# RN831X_RN861X_MCU register map
File version: v0.0.1
CPU: RN831X_RN861X_MCU r1p0, little endian, MPU, no FPU
Registers are 32-bit, read-write, reset 0x0 unless marked. A register's access mark holds for its fields unless they carry their own. Offsets are from the block's base; [hi:lo] are bit positions.

## SPI0_CORE0 — SPI0 Module core0
Base 0x20038000
Same registers: SPI1_CORE0 0x2003C000, SPI2_CORE0 0x20040000, SPI3_CORE0 0x20044000, SPI0_CORE1 0xA0038000, SPI1_CORE1 0xA003C000, SPI2_CORE1 0xA0040000, SPI3_CORE1 0xA0044000
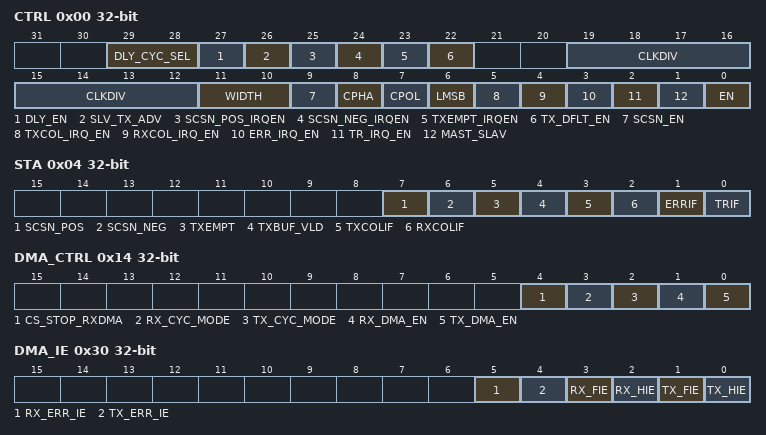
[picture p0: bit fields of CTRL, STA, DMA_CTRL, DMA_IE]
0x00 CTRL — Control Register
  [29:28] DLY_CYC_SEL — Data delay selection (valid only in DMA master mode when delay is enabled).
    0=1CYCLE (Insert 1 SPI_CLK delay per 8-bit data); 1=2CYCLE (Insert 2 SPI_CLK delays per 8-bit data); 2=4CYCLE (Insert 4 SPI_CLK delays per 8-bit data); 3=8CYCLE (Insert 8 SPI_CLK delays per 8-bit data)
  [27] DLY_EN — Delay enable (DMA master mode)
  [26] SLV_TX_ADV — SPI slave high-speed mode enable
  [25] SCSN_POS_IRQEN — SCSN rising edge interrupt enable
  [24] SCSN_NEG_IRQEN — SCSN falling edge interrupt enable
  [23] TXEMPT_IRQEN — TX empty interrupt enable
  [22] TX_DFLT_EN — Behavior when TX buffer is empty
  [19:12] CLKDIV — SCK clock divider factor
  [11:10] WIDTH — Data width selection
    0=8BIT (Data length for SPI transfer: 8 bits); 1=16BIT (Data length for SPI transfer: 16 bits); 2=32BIT (Data length for SPI transfer: 32 bits)
  [9] SCSN_EN — SCSN mode error detection enable (master mode only)
  [8] CPHA — Clock phase selection
  [7] CPOL — Clock polarity
  [6] LMSB — MSB/LSB first selection
  [5] TXCOL_IRQ_EN — TX data conflict interrupt enable
  [4] RXCOL_IRQ_EN — RX data conflict interrupt enable
  [3] ERR_IRQ_EN — SCSN Mode Error Interrupt Enable
  [2] TR_IRQ_EN — Data Transfer Interrupt Enable
  [1] MAST_SLAV — Master/Slave Mode Selection
  [0] EN — SPI Interface Enable
0x04 STA access per field — Status Register
  [7] SCSN_POS rw write-1-clears — Slave mode: CSN rising event flag
  [6] SCSN_NEG rw write-1-clears — Slave mode: CSN falling event flag
  [5] TXEMPT rw write-1-clears — TX empty conflict flag
  [4] TXBUF_VLD ro — TX buffer valid flag
  [3] TXCOLIF rw write-1-clears — TX conflict flag
  [2] RXCOLIF rw write-1-clears — RX overflow flag
  [1] ERRIF rw write-1-clears — SCSN mode error flag
  [0] TRIF rw write-1-clears — Transfer complete flag
0x08 TXDATA access not given — Transmit Data Register
  [31:0] TXDATA — Transmit Data Register. Write valid when enabled.
0x0C RXDATA access not given — Receive Data Register
0x10 TXDFLT access not given — Default Transmit Data Register
0x14 DMA_CTRL — DMA Control Register
  [4] CS_STOP_RXDMA — Disable RX_DMA_EN upon detection of SCSN high level
  [3] RX_CYC_MODE — Receive Cycle Mode Enable
  [2] TX_CYC_MODE — Transmit Cycle Mode Enable
  [1] RX_DMA_EN — Receive DMA Enable
  [0] TX_DMA_EN — Transmit DMA Enable
0x18 DMA_TBADR access not given — DMA Transmit Base Address Register
  [17:0] DMA_TBADR — DMA Transmit Start Address (Byte address).
0x1C DMA_RBADR access not given — DMA Receive Base Address Register
  [17:0] DMA_RBADR — DMA Receive Base Address (Byte address).
0x20 DMA_TLEN access not given — DMA Transmit Length Register
  [17:0] DMA_TLEN — DMA Transmit Length (in Bytes).
0x24 DMA_RLEN access not given — DMA Receive Length Register
  [17:0] DMA_RLEN — DMA Receive Length (in Bytes).
0x28 DMA_TADR ro — Current DMA Transmit Address Register
  [17:0] DMA_TADR — Current DMA Transmit Address (Byte address).
0x2C DMA_RADR ro — Current DMA Receive Address Register
  [17:0] DMA_RADR — Current DMA Receive Address (Byte address).
0x30 DMA_IE — DMA Interrupt Enable Register
  [5] RX_ERR_IE — Receive Data Overwrite Interrupt Enable
  [4] TX_ERR_IE — Transmit Data Error Interrupt Enable
  [3] RX_FIE — DMA Receive Full (Complete) Interrupt Enable
  [2] RX_HIE — DMA Receive Half Interrupt Enable
  [1] TX_FIE — DMA Transmit Full (Complete) Interrupt Enable
  [0] TX_HIE — DMA Transmit Half Interrupt Enable
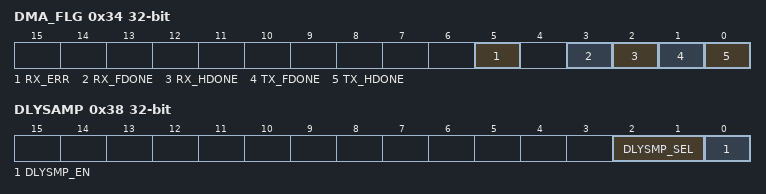
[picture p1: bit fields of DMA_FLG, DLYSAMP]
0x34 DMA_FLG — DMA Interrupt Flag Register
  [5] RX_ERR write-1-clears — Receive Data Overwrite Flag
  [3] RX_FDONE write-1-clears — DMA Receive Full (Complete) Interrupt Flag
  [2] RX_HDONE write-1-clears — DMA Receive Half Interrupt Flag
  [1] TX_FDONE write-1-clears — DMA Transmit Full (Complete) Interrupt Flag
  [0] TX_HDONE write-1-clears — DMA Transmit Half Interrupt Flag
0x38 DLYSAMP — Sample Delay Configuration Register
  [2:1] DLYSMP_SEL — Master Mode SPI Receive Data Sample Delay Selection
    0=1CYCLE (Delay sampling by 1 sys_clk cycle); 1=2CYCLE (Delay sampling by 2 sys_clk cycles); 2=3CYCLE (Delay sampling by 3 sys_clk cycles); 3=4CYCLE (Delay sampling by 4 sys_clk cycles)
  [0] DLYSMP_EN — SPI Receive Data Sample Delay Enable
